# DCAN register map
Vendor: Texas Instruments
Peripheral module from a debugger description file (folder am437x).
Registers are 32-bit, read-only, no defined reset value unless marked. A register's access mark holds for its fields unless they carry their own. Offsets are as the file gives them; lines under a group give offsets from that group; [hi:lo] are bit positions; {n}, {i} and the like mark numbered series; 'fields as' and 'values as' point back to an identical list; <NAME> marks a mode.

## DCAN (part 1 of 2)
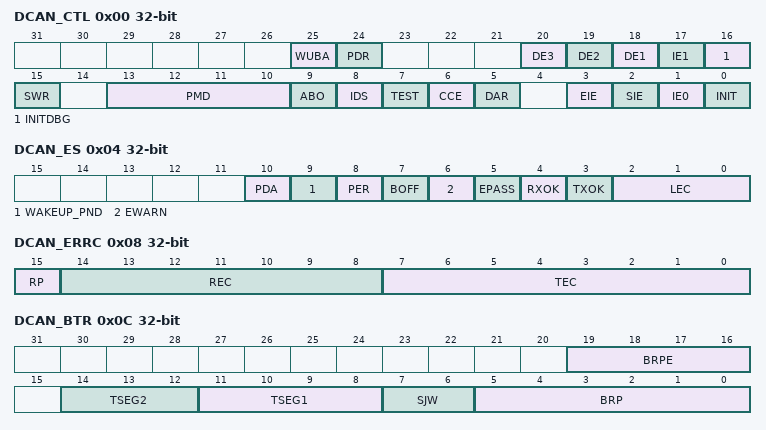
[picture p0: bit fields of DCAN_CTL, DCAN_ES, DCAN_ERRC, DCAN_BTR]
0x00 DCAN_CTL access per field — The Bus-Off recovery sequence (refer to CAN specification) cannot be shortened by setting or resetting Init bit. If the module goes Bus-Off, it will automatically set the Init bit and stop all bus activities. When the Init bit is cleared by the application again, the module will then wait for 129 occurrences of Bus Idle (129 * 11 consecutive recessive bits) before resuming normal operation. At the end of the bus-off recovery sequence, the error counters will be reset. After the Init bit is reset, each time when a sequence of 11 recessive bits is monitored, a Bit0 error code is written to the error and status register, enabling the CPU to check whether the CAN bus is stuck at dominant or continuously disturbed, and to monitor the proceeding of the bus-off recovery sequence.
  [25] WUBA rw — Automatic wake up on bus activity when in local power-down mode. [[br]]Note: The CAN message, which initiates the bus activity, cannot be received. [[br]]This means that the first message received in power down and automatic wake-up mode, will be lost.
    1=en_2_0x1 (Detection of a dominant CAN bus level while in local power-down mode is enabled. On occurrence of a dominant CAN bus level, the wake up sequence is started.); 0=en_1_0x0 (No detection of a dominant CAN bus level while in local power-down mode.)
  [24] PDR rw — Request for local low power-down mode
    1=en_2_0x1 (Local power-down mode has been requested by application. The DCAN will acknowledge the local power-down mode by setting bit PDA in the error and status register. The local clocks will be turned off by DCAN internal logic.); 0=en_1_0x0 (No application request for local low power-down mode. If the application has cleared this bit while DCAN in local power-down mode, also the Init bit has to be cleared.)
  [20] DE3 rw — Enable DMA request line for IF3. [[br]]Note: A pending DMA request for IF3 remains active until first access to one of the IF3 registers.
    1=en_2_0x1 (Enabled); 0=en_1_0x0 (Disabled)
  [19] DE2 rw — Enable DMA request line for IF2. [[br]]Note: A pending DMA request for IF2 remains active until first access to one of the IF2 registers.
    1=en_2_0x1 (Enabled); 0=en_1_0x0 (Disabled)
  [18] DE1 rw — Enable DMA request line for IF1. [[br]]Note: A pending DMA request for IF1 remains active until first access to one of the IF1 registers.
    1=en_2_0x1 (Enabled); 0=en_1_0x0 (Disabled)
  [17] IE1 rw — Interrupt line 1 enable
    1=en_2_0x1 (Enabled - interrupts will assert line DCAN1INT to one; line remains active until pending interrupts are processed.); 0=en_1_0x0 (Disabled - Module interrupt DCAN1INT is always low.)
  [16] INITDBG ro — Internal init state while debug access
    1=en_2_0x1 (Debug mode requested and internally entered; the DCAN is ready for debug accesses.); 0=en_1_0x0 (Not in debug mode, or debug mode requested but not entered.)
  [15] SWR rw — SW reset enable. [[br]]Note: To execute software reset, the following procedure is necessary: (a) Set Init bit to shut down CAN communication and (b) Set SWR bit additionally to Init bit.
    1=en_2_0x1 (Module is forced to reset state. This bit will automatically get cleared after execution of SW reset after one OCP clock cycle.); 0=en_1_0x0 (Normal Operation)
  [13:10] PMD rw — Parity on/off. [[br]]5 = Parity function disabled. [[br]]Others = Parity function enabled.
  [9] ABO rw — Auto-Bus-On enable
    1=en_2_0x1 (The Auto-Bus-On feature is enabled); 0=en_1_0x0 (The Auto-Bus-On feature is disabled)
  [8] IDS rw — Interruption debug support enable
    1=en_2_0x1 (When Debug/Suspend mode is requested, DCAN will interrupt any transmission or reception, and enter Debug/Suspend mode immediately.); 0=en_1_0x0 (When Debug/Suspend mode is requested, DCAN will wait for a started transmission or reception to be completed before entering Debug/Suspend mode)
  [7] TEST rw — Test mode enable
    1=en_2_0x1 (Test Mode); 0=en_1_0x0 (Normal Operation)
  [6] CCE rw — Configuration change enable
    1=en_2_0x1 (The CPU has write access to the configuration registers (when Init bit is set).); 0=en_1_0x0 (The CPU has no write access to the configuration registers.)
  [5] DAR rw — Disable automatic retransmission
    1=en_2_0x1 (Automatic retransmission disabled.); 0=en_1_0x0 (Automatic retransmission of not successful messages enabled.)
  [3] EIE rw — Error interrupt enable
    1=en_2_0x1 (Enabled - PER, BOff and EWarn bits can generate an interrupt at DCAN0INT line and affect the interrupt register.); 0=en_1_0x0 (Disabled - PER, BOff and EWarn bits can not generate an interrupt.)
  [2] SIE rw — Status change interrupt enable
    1=en_2_0x1 (Enabled - WakeUpPnd, RxOk, TxOk and LEC can generate an interrupt at DCAN0INT line and affect the interrupt register.); 0=en_1_0x0 (Disabled - WakeUpPnd, RxOk, TxOk and LEC bits can not generate an interrupt.)
  [1] IE0 rw — Interrupt line 0 enable
    1=en_2_0x1 (Enabled - interrupts will assert line DCAN0INT to one; line remains active until pending interrupts are processed.); 0=en_1_0x0 (Disabled - Module interrupt DCAN0INT is always low.)
  [0] INIT rw — Initialization
    1=en_2_0x1 (Initialization mode is entered); 0=en_1_0x0 (Normal operation)
0x04 DCAN_ES access not given — Interrupts are generated by bits PER, BOff and EWarn (if EIE bit in CAN control register is set) and by bits WakeUpPnd, RxOk, TxOk, and LEC (if SIE bit in CAN control register is set). A change of bit EPass will not generate an interrupt. Reading the error and status register clears the WakeUpPnd, PER, RxOk and TxOk bits and set the LEC to value '7.' Additionally, the status interrupt value (0x8000) in the interrupt register will be replaced by the next lower priority interrupt value. The EOI for all other interrupts (DCANINT0 and DCANINT1) are automatically handled by hardware. For debug support, the auto clear functionality of error and status register (clear of status flags by read) is disabled when in debug/suspend mode.
  [10] PDA ro — Local power-down mode acknowledge
    1=en_2_0x1 (Application request for setting DCAN to local power-down mode was successful. DCAN is in local power-down mode.); 0=en_1_0x0 (DCAN is not in local power-down mode.)
  [9] WAKEUP_PND — Wake up pending. [[br]]This bit can be used by the CPU to identify the DCAN as the source to wake up the system. [[br]]This bit will be reset if error and status register is read.
    1=en_2_0x1 (DCAN has initiated a wake up of the system due to dominant CAN bus while module power down.); 0=en_1_0x0 (No Wake Up is requested by DCAN.)
  [8] PER — Parity error detected. [[br]]This bit will be reset if error and status register is read.
    1=en_2_0x1 (The parity check mechanism has detected a parity error in the Message RAM.); 0=en_1_0x0 (No parity error has been detected since last read access.)
  [7] BOFF ro — Bus-Off state
    1=en_2_0x1 (The CAN module is in bus-off state.); 0=en_1_0x0 (The CAN module is not bus-off state.)
  [6] EWARN ro — Warning state
    1=en_2_0x1 (At least one of the error counters has reached the error warning limit of 96.); 0=en_1_0x0 (Both error counters are below the error warning limit of 96.)
  [5] EPASS ro — Error passive state
    1=en_2_0x1 (The CAN core is in the error passive state as defined in the CAN Specification.); 0=en_1_0x0 (On CAN Bus error, the DCAN could send active error frames.)
  [4] RXOK — Received a message successfully. [[br]]This bit will be reset if error and status register is read.
    1=en_2_0x1 (A message has been successfully received since the last time when this bit was reset by a read access of the CPU (independent of the result of acceptance filtering).); 0=en_1_0x0 (No message has been successfully received since the last time when this bit was read by the CPU. This bit is never reset by DCAN internal events.)
  [3] TXOK — Transmitted a message successfully. [[br]]This bit will be reset if error and status register is read.
    1=en_2_0x1 (A message has been successfully transmitted (error free and acknowledged by at least one other node) since the last time when this bit was reset by a read access of the CPU.); 0=en_1_0x0 (No message has been successfully transmitted since the last time when this bit was read by the CPU. This bit is never reset by DCAN internal events.)
  [2:0] LEC — Last error code. [[br]]The LEC field indicates the type of the last error on the CAN bus. [[br]]This field will be cleared to '0' when a message has been transferred (reception or transmission) without error.
    7=en_8_0x7 (No CAN bus event was detected since the last time the CPU read the error and status register. Any read access to the error and status register re-initializes the LEC to value '7.'); 6=en_7_0x6 (CRC error. In a received message, the CRC check sum was incorrect. (CRC received for an incoming message does not match the calculated CRC for the received data).); 5=en_6_0x5 (Bit0 error. During the transmission of a message (or acknowledge bit, or active error flag, or overload flag), the device wanted to send a dominant level (logical value '0'), but the monitored bus level was recessive. During Bus-Off recovery, this status is set each time a sequence of 11 recessive bits has been monitored. This enables the CPU to monitor the proceeding of the Bus-Off recovery sequence (indicating the bus is not stuck at dominant or continuously disturbed).); 4=en_5_0x4 (Bit1 error. During the transmission of a message (with the exception of the arbitration field), the device wanted to send a recessive level (bit of logical value '1'), but the monitored bus value was dominant.); 3=en_4_0x3 (Ack error. The message this CAN core transmitted was not acknowledged by another node.); 2=en_3_0x2 (Form error. A fixed format part of a received frame has the wrong format.); 1=en_2_0x1 (Stuff error. More than five equal bits in a row have been detected in a part of a received message where this is not allowed.); 0=en_1_0x0 (No error)
0x08 DCAN_ERRC
  [15] RP — Receive error passive
    1=en_2_0x1 (The receive error counter has reached the error passive level as defined in the CAN specification.); 0=en_1_0x0 (The receive error counter is below the error passive level.)
  [14:8] REC — Receive error counter. [[br]]Actual state of the receive error counter (values from 0 to 255).
  [7:0] TEC — Transmit error counter. [[br]]Actual state of the transmit error counter (values from 0 to 255).
0x0C DCAN_BTR access not given — This register is only writable if CCE and Init bits in the CAN control register are set. The CAN bit time may be programmed in the range of 8 to 25 time quanta. The CAN time quantum may be programmed in the range of 1 to1024 CAN_CLK periods. With a CAN_CLK of 8 MHz and BRPE = 0x00, the reset value of 0x00002301 configures the DCAN for a bit rate of 500kBit/s.
  [19:16] BRPE ro — Baud rate prescaler extension. [[br]]Valid programmed values are 0 to 15. [[br]]By programming BRPE the baud rate prescaler can be extended to values up to 1024.
  [14:12] TSEG2 — Time segment after the sample point. [[br]]Valid programmed values are 0 to 7. [[br]]The actual TSeg2 value which is interpreted for the bit timing will be the programmed TSeg2 value + 1.
  [11:8] TSEG1 — Time segment before the sample point. [[br]]Valid programmed values are 1 to 15. [[br]]The actual TSeg1 value interpreted for the bit timing will be the programmed TSeg1 value + 1.
  [7:6] SJW — Synchronization Jump Width. [[br]]Valid programmed values are 0 to 3. [[br]]The actual SJW value interpreted for the synchronization will be the programmed SJW value + 1.
  [5:0] BRP — Baud rate prescaler. [[br]]Value by which the CAN_CLK frequency is divided for generating the bit time quanta. [[br]]The bit time is built up from a multiple of this quanta. [[br]]Valid programmed values are 0 to 63. [[br]]The actual BRP value interpreted for the bit timing will be the programmed BRP value + 1.
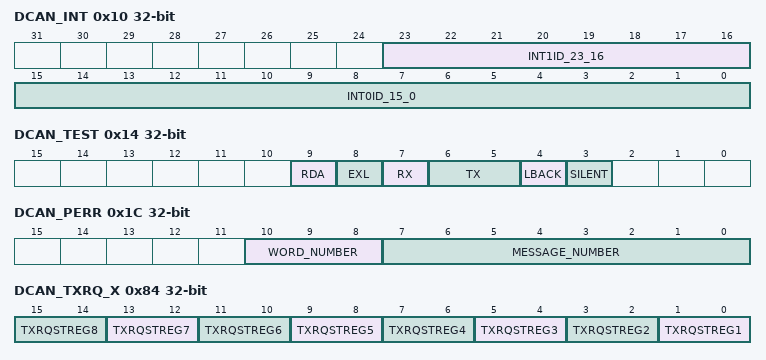
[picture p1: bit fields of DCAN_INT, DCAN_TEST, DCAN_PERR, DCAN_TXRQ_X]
0x10 DCAN_INT
  [23:16] INT1ID_23_16 — Interrupt 1 Identifier (indicates the message object with the highest pending interrupt). [[br]]If several interrupts are pending, the CAN interrupt register will point to the pending interrupt with the highest priority. [[br]]The DCAN1INT interrupt line remains active until Int1ID reaches value 0 (the cause of the interrupt is reset) or until IE1 is cleared. [[br]]A message interrupt is cleared by clearing the message object's IntPnd bit. [[br]]Among the message interrupts, the message object's interrupt priority decreases with increasing message number. [[br]]0x[[br]]00: No interrupt is pending. [[br]]0x[[br]]01-0x[[br]]80: Number of message object which caused the interrupt. [[br]]0xFF: Unused.
  [15:0] INT0ID_15_0 — Interrupt Identifier (the number here indicates the source of the interrupt). [[br]]If several interrupts are pending, the CAN interrupt register will point to the pending interrupt with the highest priority. [[br]]The DCAN0INT interrupt line remains active until Int0ID reaches value 0 (the cause of the interrupt is reset) or until IE0 is cleared. [[br]]The Status interrupt has the highest priority. [[br]]Among the message interrupts, the message object's interrupt priority decreases with increasing message number. [[br]]0x[[br]]0000: No interrupt is pending. [[br]]0x[[br]]0001-0x[[br]]0080: Number of message object which caused the interrupt. [[br]]0x[[br]]0081-0x7FFF: Unused (values 0081 to 7FFF). [[br]]0x[[br]]8000: Error and status register value is not 0x07. [[br]]0xFFFF: Unused.
0x14 DCAN_TEST access not given — For all test modes, the test bit in CAN control register needs to be set to one. If test bit is set, the RDA, EXL, Tx1, Tx0, LBack and Silent bits are writable. Bit Rx monitors the state of pin CAN_RX and therefore is only readable. All test register functions are disabled when test bit is cleared. The test register is only writable if test bit in CAN control register is set. Setting Tx[1:0] other than '00' will disturb message transfer. When the internal loop-back mode is active (bit LBack is set), bit EXL will be ignored.
  [9] RDA — RAM direct access enable
    1=en_2_0x1 (Direct access to the RAM is enabled while in test mode); 0=en_1_0x0 (Normal operation)
  [8] EXL — External loopback mode
    1=en_2_0x1 (Enabled); 0=en_1_0x0 (Disabled)
  [7] RX ro — Receive pin. [[br]]Monitors the actual value of the CAN_RX pin
    1=en_2_0x1 (The CAN bus is recessive); 0=en_1_0x0 (The CAN bus is dominant)
  [6:5] TX — Control of CAN_TX pin.
  [4] LBACK — Loopback mode
    1=en_2_0x1 (Enabled); 0=en_1_0x0 (Disabled)
  [3] SILENT — Silent mode
    1=en_2_0x1 (Enabled); 0=en_1_0x0 (Disabled)
0x1C DCAN_PERR — If a parity error is detected, the PER flag will be set in the error and status register. This bit is not reset by the parity check mechanism; it must be reset by reading the error and status register. In addition to the PER flag, the parity error code register will indicate the memory area where the parity error has been detected (message number and word number). If more than one word with a parity error was detected, the highest word number with a parity error will be displayed. After a parity error has been detected, the register will hold the last error code until power is removed.
  [10:8] WORD_NUMBER — Word number where parity error has been detected. [[br]]0x[[br]]01-0x[[br]]05: RDA word number (1 to 5) of the message object (according to the message RAM representation in RDA mode).
  [7:0] MESSAGE_NUMBER — Message number. [[br]]0x[[br]]01-0x[[br]]80: Message object number where parity error has been detected.
0x80 DCAN_ABOTR rw — On write access to the CAN control register while Auto-Bus-On timer is running, the Auto-Bus-On procedure will be aborted. During Debug/Suspend mode, running Auto-Bus-On timer will be paused.
  [31:0] ABO_TIME — Number of OCP clock cycles before a Bus-Off recovery sequence is started by clearing the Init bit. [[br]]This function has to be enabled by setting bit ABO in CAN control register. [[br]]The Auto-Bus-On timer is realized by a 32 bit counter that starts to count down to zero when the module goes Bus-Off. [[br]]The counter will be reloaded with the preload value of the ABO time register after this phase.
0x84 DCAN_TXRQ_X — Example 1. Bit 0 of the transmission request X register represents byte 0 of the transmission request 1 register. If one or more bits in this byte are set, bit 0 of the transmission request X register will be set.
  [2n-1:2n-2] TXRQSTREG{n} (n=1..8)
0x88 DCAN_TXRQ12 — The TXRQ12 to TXRQ78 registers hold the TxRqst bits of the implemented message objects. By reading out these bits, the CPU can check for pending transmission requests. The TxRqst bit in a specific message object can be set/reset by the CPU via the IF1/IF2 message interface registers, or by the message handler after reception of a remote frame or after a successful transmission.
  [31:0] TXRQS — Transmission request bits [0:31] (for all message objects)
    1=en_2_0x1 (The transmission of this message object is requested and is not yet done.); 0=en_1_0x0 (No transmission has been requested for this message object.)
0x8C DCAN_TXRQ34 — The TXRQ12 to TXRQ78 registers hold the TxRqst bits of the implemented message objects. By reading out these bits, the CPU can check for pending transmission requests. The TxRqst bit in a specific message object can be set/reset by the CPU via the IF1/IF2 message interface registers, or by the message handler after reception of a remote frame or after a successful transmission.
  [31:0] TXRQS — Transmission request bits [32:63] (for all message objects)
    values as DCAN_TXRQ12.TXRQS
0x90 DCAN_TXRQ56 — The TXRQ12 to TXRQ78 registers hold the TxRqst bits of the implemented message objects. By reading out these bits, the CPU can check for pending transmission requests. The TxRqst bit in a specific message object can be set/reset by the CPU via the IF1/IF2 message interface registers, or by the message handler after reception of a remote frame or after a successful transmission.
  [31:0] TXRQS — Transmission request bits [64:95] (for all message objects)
    values as DCAN_TXRQ12.TXRQS
0x94 DCAN_TXRQ78 — The TXRQ12 to TXRQ78 registers hold the TxRqst bits of the implemented message objects. By reading out these bits, the CPU can check for pending transmission requests. The TxRqst bit in a specific message object can be set/reset by the CPU via the IF1/IF2 message interface registers, or by the message handler after reception of a remote frame or after a successful transmission.
  [31:0] TXRQS — Transmission request bits [96:127] (for all message objects)
    values as DCAN_TXRQ12.TXRQS
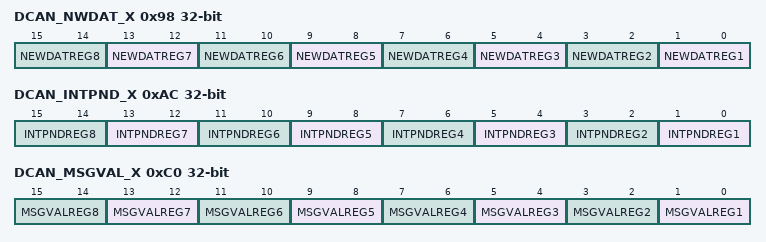
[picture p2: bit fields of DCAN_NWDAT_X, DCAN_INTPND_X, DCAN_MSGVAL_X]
0x98 DCAN_NWDAT_X — With the new data X register, the CPU can detect if one or more bits in the different new data registers are set. Each register bit represents a group of eight message objects. If at least on of the NewDat bits of these message objects are set, the corresponding bit in the new data X register will be set. Example 1. Bit 0 of the new data X register represents byte 0 of the new data 1 register. If one or more bits in this byte are set, bit 0 of the new data X register will be set.
  [2n-1:2n-2] NEWDATREG{n} (n=1..8)
0x9C DCAN_NWDAT12 — These registers hold the NewDat bits of the implemented message objects. By reading out these bits, the CPU can check for new data in the message objects. The NewDat bit of a specific message object can be set/reset by the CPU via the IF1/IF2 interface register sets, or by the message handler after reception of a data frame or after a successful transmission.
  [31:0] NEWDAT — New Data Bits [0:31] (for all message objects)
    1=en_2_0x1 (The message handler or the CPU has written new data into the data portion of this message object.); 0=en_1_0x0 (No new data has been written into the data portion of this message object by the message handler since the last time when this flag was cleared by the CPU.)
0xA0 DCAN_NWDAT34 — These registers hold the NewDat bits of the implemented message objects. By reading out these bits, the CPU can check for new data in the message objects. The NewDat bit of a specific message object can be set/reset by the CPU via the IF1/IF2 interface register sets, or by the message handler after reception of a data frame or after a successful transmission.
  [31:0] NEWDAT — New Data Bits [32:63] (for all message objects)
    values as DCAN_NWDAT12.NEWDAT
0xA4 DCAN_NWDAT56 — These registers hold the NewDat bits of the implemented message objects. By reading out these bits, the CPU can check for new data in the message objects. The NewDat bit of a specific message object can be set/reset by the CPU via the IF1/IF2 interface register sets, or by the message handler after reception of a data frame or after a successful transmission.
  [31:0] NEWDAT — New Data Bits [64:95] (for all message objects)
    values as DCAN_NWDAT12.NEWDAT
0xA8 DCAN_NWDAT78 — These registers hold the NewDat bits of the implemented message objects. By reading out these bits, the CPU can check for new data in the message objects. The NewDat bit of a specific message object can be set/reset by the CPU via the IF1/IF2 interface register sets, or by the message handler after reception of a data frame or after a successful transmission.
  [31:0] NEWDAT — New Data Bits [96:127] (for all message objects)
    values as DCAN_NWDAT12.NEWDAT
0xAC DCAN_INTPND_X — With the interrupt pending X register, the CPU can detect if one or more bits in the different interrupt pending registers are set. Each bit of this register represents a group of eight message objects. If at least one of the IntPnd bits of these message objects are set, the corresponding bit in the interrupt pending X register will be set. Example 2. Bit 0 of the interrupt pending X register represents byte 0 of the interrupt pending 1 register. If one or more bits in this byte are set, bit 0 of the interrupt pending X register will be set.
  [2n-1:2n-2] INTPNDREG{n} (n=1..8)
0xB0 DCAN_INTPND12 — These registers hold the IntPnd bits of the implemented message objects. By reading out these bits, the CPU can check for pending interrupts in the message objects. The IntPnd bit of a specific message object can be set/reset by the CPU via the IF1/IF2 interface register sets, or by the message handler after a reception or a successful transmission.
  [31:0] INTPND — Interrupt Pending Bits [0:31] (for all message objects)
    1=en_2_0x1 (This message object is the source of an interrupt.); 0=en_1_0x0 (This message object is not the source of an interrupt.)
0xB4 DCAN_INTPND34 — These registers hold the IntPnd bits of the implemented message objects. By reading out these bits, the CPU can check for pending interrupts in the message objects. The IntPnd bit of a specific message object can be set/reset by the CPU via the IF1/IF2 interface register sets, or by the message handler after a reception or a successful transmission.
  [31:0] INTPND — Interrupt Pending Bits [32:63] (for all message objects)
    values as DCAN_INTPND12.INTPND
0xB8 DCAN_INTPND56 — These registers hold the IntPnd bits of the implemented message objects. By reading out these bits, the CPU can check for pending interrupts in the message objects. The IntPnd bit of a specific message object can be set/reset by the CPU via the IF1/IF2 interface register sets, or by the message handler after a reception or a successful transmission.
  [31:0] INTPND — Interrupt Pending Bits [64:95] (for all message objects)
    values as DCAN_INTPND12.INTPND
0xBC DCAN_INTPND78 — These registers hold the IntPnd bits of the implemented message objects. By reading out these bits, the CPU can check for pending interrupts in the message objects. The IntPnd bit of a specific message object can be set/reset by the CPU via the IF1/IF2 interface register sets, or by the message handler after a reception or a successful transmission.
  [31:0] INTPND — Interrupt Pending Bits [96:127] (for all message objects)
    values as DCAN_INTPND12.INTPND
0xC0 DCAN_MSGVAL_X — With the message valid X register, the CPU can detect if one or more bits in the different message valid registers are set. Each bit of this register represents a group of eight message objects. If at least one of the MsgVal bits of these message objects are set, the corresponding bit in the message valid X register will be set. Example 3. Bit 0 of the message valid X register represents byte 0 of the message valid 1 register. If one or more bits in this byte are set, bit 0 of the message valid X register will be set.
  [2n-1:2n-2] MSGVALREG{n} (n=1..8)
0xC4 DCAN_MSGVAL12 — These registers hold the MsgVal bits of the implemented message objects. By reading out these bits, the CPU can check which message objects are valid. The MsgVal bit of a specific message object can be set/reset by the CPU via the IF1/IF2 interface register sets, or by the message handler after a reception or a successful transmission.
  [31:0] MSGVAL — Message valid bits [0:31] (for all message objects)
    1=en_2_0x1 (This message object is configured and will be considered by the message handler.); 0=en_1_0x0 (This message object is ignored by the message handler.)
0xC8 DCAN_MSGVAL34 — These registers hold the MsgVal bits of the implemented message objects. By reading out these bits, the CPU can check which message objects are valid. The MsgVal bit of a specific message object can be set/reset by the CPU via the IF1/IF2 interface register sets, or by the message handler after a reception or a successful transmission.
  [31:0] MSGVAL — Message valid bits [32:63] (for all message objects)
    values as DCAN_MSGVAL12.MSGVAL
0xCC DCAN_MSGVAL56 — These registers hold the MsgVal bits of the implemented message objects. By reading out these bits, the CPU can check which message objects are valid. The MsgVal bit of a specific message object can be set/reset by the CPU via the IF1/IF2 interface register sets, or by the message handler after a reception or a successful transmission.
  [31:0] MSGVAL — Message valid bits [64:95] (for all message objects)
    values as DCAN_MSGVAL12.MSGVAL
0xD0 DCAN_MSGVAL78 — These registers hold the MsgVal bits of the implemented message objects. By reading out these bits, the CPU can check which message objects are valid. The MsgVal bit of a specific message object can be set/reset by the CPU via the IF1/IF2 interface register sets, or by the message handler after a reception or a successful transmission.
  [31:0] MSGVAL — Message valid bits [96:127] (for all message objects)
    values as DCAN_MSGVAL12.MSGVAL
0xD8 DCAN_INTMUX12 — The IntMux flag determine for each message object, which of the two interrupt lines (DCAN0INT or DCAN1INT) will be asserted when the IntPnd of this message object is set. Both interrupt lines can be globally enabled or disabled by setting or clearing IE0 and IE1 bits in CAN control register. The IntPnd bit of a specific message object can be set or reset by the CPU via the IF1/IF2 interface register sets, or by message handler after reception or successful transmission of a frame. This will also affect the Int0ID resp Int1ID flags in the interrupt register.
  [31:0] INTMUX — IntMux[31:0] multiplexes IntPnd value to either DCAN0INT or DCAN1INT interrupt lines. [[br]]The mapping from the bits to the message objects is as follows. [[br]]Bit 0 -> last implemented message object. [[br]]Bit 1 -> message object number 1. [[br]]Bit 2 -> message object number 2. [[br]]... [[br]]Bit 31 -> message object number 31. [[br]]0x[[br]]0 = DCAN0INT line is active if corresponding IntPnd flag is one. [[br]]0x[[br]]1 = DCAN1INT line is active if corresponding IntPnd flag is one.
    1=en_2_0x1 (DCAN1INT line is active if corresponding IntPnd flag is one.); 0=en_1_0x0 (DCAN0INT line is active if corresponding IntPnd flag is one.)
0xDC DCAN_INTMUX34 — The IntMux flag determine for each message object, which of the two interrupt lines (DCAN0INT or DCAN1INT) will be asserted when the IntPnd of this message object is set. Both interrupt lines can be globally enabled or disabled by setting or clearing IE0 and IE1 bits in CAN control register. The IntPnd bit of a specific message object can be set or reset by the CPU via the IF1/IF2 interface register sets, or by message handler after reception or successful transmission of a frame. This will also affect the Int0ID resp Int1ID flags in the interrupt register.
  [31:0] INTMUX — IntMux[63:32] multiplexes IntPnd value to either DCAN0INT or DCAN1INT interrupt lines. [[br]]The mapping from the bits to the message objects is as follows. [[br]]Bit 0 -> last implemented message object. [[br]]Bit 1 -> message object number 1. [[br]]Bit 2 -> message object number 2. [[br]]... [[br]]Bit 31 -> message object number 31. [[br]]0x[[br]]0 = DCAN0INT line is active if corresponding IntPnd flag is one. [[br]]0x[[br]]1 = DCAN1INT line is active if corresponding IntPnd flag is one.
    values as DCAN_INTMUX12.INTMUX
0xE0 DCAN_INTMUX56 — The IntMux flag determine for each message object, which of the two interrupt lines (DCAN0INT or DCAN1INT) will be asserted when the IntPnd of this message object is set. Both interrupt lines can be globally enabled or disabled by setting or clearing IE0 and IE1 bits in CAN control register. The IntPnd bit of a specific message object can be set or reset by the CPU via the IF1/IF2 interface register sets, or by message handler after reception or successful transmission of a frame. This will also affect the Int0ID resp Int1ID flags in the interrupt register.
  [31:0] INTMUX — IntMux[95:64] multiplexes IntPnd value to either DCAN0INT or DCAN1INT interrupt lines. [[br]]The mapping from the bits to the message objects is as follows. [[br]]Bit 0 -> last implemented message object. [[br]]Bit 1 -> message object number 1. [[br]]Bit 2 -> message object number 2. [[br]]... [[br]]Bit 31 -> message object number 31. [[br]]0x[[br]]0 = DCAN0INT line is active if corresponding IntPnd flag is one. [[br]]0x[[br]]1 = DCAN1INT line is active if corresponding IntPnd flag is one.
    values as DCAN_INTMUX12.INTMUX
0xE4 DCAN_INTMUX78 — The IntMux flag determine for each message object, which of the two interrupt lines (DCAN0INT or DCAN1INT) will be asserted when the IntPnd of this message object is set. Both interrupt lines can be globally enabled or disabled by setting or clearing IE0 and IE1 bits in CAN control register. The IntPnd bit of a specific message object can be set or reset by the CPU via the IF1/IF2 interface register sets, or by message handler after reception or successful transmission of a frame. This will also affect the Int0ID resp Int1ID flags in the interrupt register.
  [31:0] INTMUX — IntMux[127:96] multiplexes IntPnd value to either DCAN0INT or DCAN1INT interrupt lines. [[br]]The mapping from the bits to the message objects is as follows. [[br]]Bit 0 -> last implemented message object. [[br]]Bit 1 -> message object number 1. [[br]]Bit 2 -> message object number 2. [[br]]... [[br]]Bit 31 -> message object number 31. [[br]]0x[[br]]0 = DCAN0INT line is active if corresponding IntPnd flag is one. [[br]]0x[[br]]1 = DCAN1INT line is active if corresponding IntPnd flag is one.
    values as DCAN_INTMUX12.INTMUX
